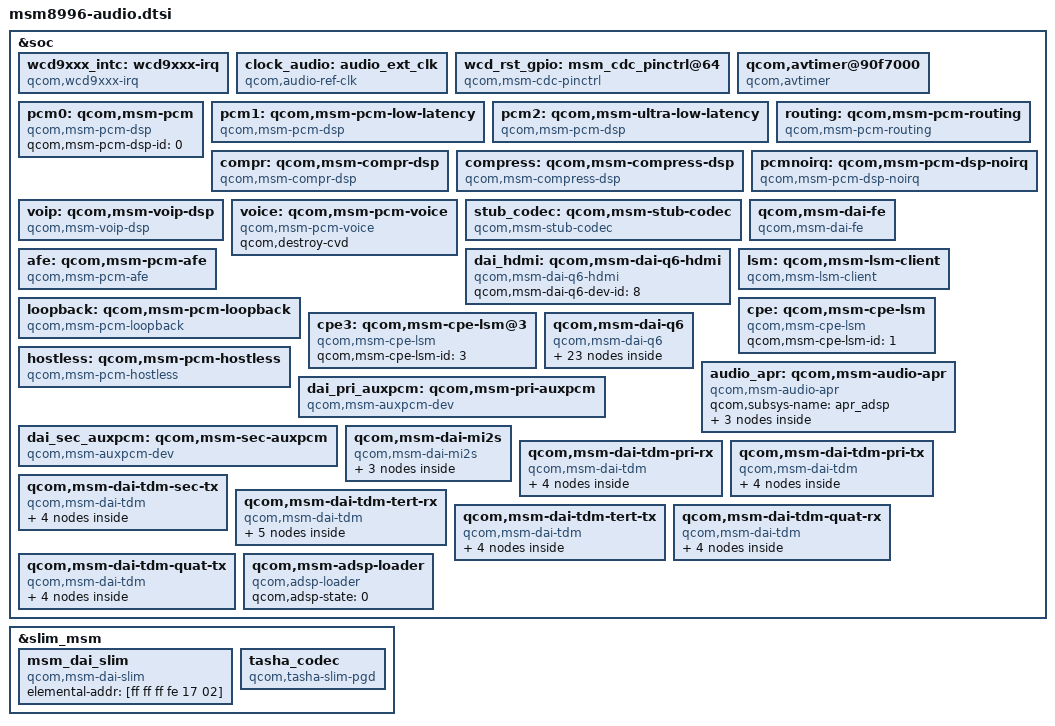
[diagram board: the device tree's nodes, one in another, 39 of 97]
/* Copyright (c) 2014-2017, The Linux Foundation. All rights reserved.
 *
 * Copyright (c) 2019 AngeloGioacchino Del Regno <kholk11@gmail.com>
 *
 * This program is free software; you can redistribute it and/or modify
 * it under the terms of the GNU General Public License version 2 and
 * only version 2 as published by the Free Software Foundation.
 *
 * This program is distributed in the hope that it will be useful,
 * but WITHOUT ANY WARRANTY; without even the implied warranty of
 * MERCHANTABILITY or FITNESS FOR A PARTICULAR PURPOSE.  See the
 * GNU General Public License for more details.
 */

#include <dt-bindings/clock/qcom,gcc-msm8996.h>
#include <dt-bindings/clock/qcom,mmcc-msm8996.h>
#include <dt-bindings/clock/qcom,audio-ext-clk.h>
#include <dt-bindings/spmi/spmi.h>
#include <dt-bindings/interrupt-controller/arm-gic.h>

&soc {
	wcd9xxx_intc: wcd9xxx-irq {
		compatible = "qcom,wcd9xxx-irq";
		interrupt-controller;
		#interrupt-cells = <1>;
		interrupt-parent = <&tlmm>;
		qcom,gpio-connect = <&tlmm 54 0>;
		pinctrl-names = "default";
		pinctrl-0 = <&wcd_intr_default>;
	};

	clock_audio: audio_ext_clk {
		compatible = "qcom,audio-ref-clk";
		qcom,audio-ref-clk-gpio = <&pm8994_gpios 15 0>; /* NOT IMPLEMENTED YET */

		qcom,codec-ext-clk-src = <3>;		    /* AUDIO_EXT_CLK_LPASS2 */
		qcom,codec-lpass-ext-clk-freq = <11289600>; /* IBIT_CLK_11_P2896_MHZ */
		qcom,codec-lpass-clk-id = <266>;	    /* SPEAKER_I2S_OSR */

		clock-names = "osr_clk";
		clocks = <&clock_rpmcc RPM_SMD_DIV_CLK1>;
		pmic-clock-names = "div_clk1";

		#clock-cells = <1>;
		qcom,use-pinctrl = <1>;
		pinctrl-names = "sleep", "active";
		pinctrl-0 = <&spkr_i2s_clk_sleep>;
		pinctrl-1 = <&spkr_i2s_clk_active>;
	};

	wcd_rst_gpio: msm_cdc_pinctrl@64 {
		compatible = "qcom,msm-cdc-pinctrl";
		qcom,cdc-rst-n-gpio = <&tlmm 64 0>;
		pinctrl-names = "aud_active", "aud_sleep";
		pinctrl-0 = <&cdc_reset_active>;
		pinctrl-1 = <&cdc_reset_sleep>;
	};

	qcom,avtimer@90f7000 {
		compatible = "qcom,avtimer";
		reg = <0x90f700c 0x4>,
		      <0x90f7010 0x4>;
		reg-names = "avtimer_lsb_addr", "avtimer_msb_addr";
		qcom,clk-div = <27>;
	};

	pcm0: qcom,msm-pcm {
		compatible = "qcom,msm-pcm-dsp";
		qcom,msm-pcm-dsp-id = <0>;
	};

	pcm1: qcom,msm-pcm-low-latency {
		compatible = "qcom,msm-pcm-dsp";
		qcom,msm-pcm-dsp-id = <1>;
		qcom,msm-pcm-low-latency;
		qcom,latency-level = "regular";
	};

	pcm2: qcom,msm-ultra-low-latency {
		compatible = "qcom,msm-pcm-dsp";
		qcom,msm-pcm-dsp-id = <2>;
		qcom,msm-pcm-low-latency;
		qcom,latency-level = "ultra";
	};

	routing: qcom,msm-pcm-routing {
		compatible = "qcom,msm-pcm-routing";
	};

	compr: qcom,msm-compr-dsp {
		compatible = "qcom,msm-compr-dsp";
	};

	compress: qcom,msm-compress-dsp {
		compatible = "qcom,msm-compress-dsp";
	};

	pcmnoirq: qcom,msm-pcm-dsp-noirq {
		compatible = "qcom,msm-pcm-dsp-noirq";
		qcom,msm-pcm-low-latency;
		qcom,latency-level = "ultra";
	};

	voip: qcom,msm-voip-dsp {
		compatible = "qcom,msm-voip-dsp";
	};

	voice: qcom,msm-pcm-voice {
		compatible = "qcom,msm-pcm-voice";
		qcom,destroy-cvd;
	};

	stub_codec: qcom,msm-stub-codec {
		compatible = "qcom,msm-stub-codec";
	};

	qcom,msm-dai-fe {
		compatible = "qcom,msm-dai-fe";
	};

	afe: qcom,msm-pcm-afe {
		compatible = "qcom,msm-pcm-afe";
	};

	dai_hdmi: qcom,msm-dai-q6-hdmi {
		compatible = "qcom,msm-dai-q6-hdmi";
		qcom,msm-dai-q6-dev-id = <8>;
	};

	lsm: qcom,msm-lsm-client {
		compatible = "qcom,msm-lsm-client";
	};

	loopback: qcom,msm-pcm-loopback {
		compatible = "qcom,msm-pcm-loopback";
	};

	cpe: qcom,msm-cpe-lsm {
		compatible = "qcom,msm-cpe-lsm";
		qcom,msm-cpe-lsm-id = <1>;
	};

	cpe3: qcom,msm-cpe-lsm@3 {
		compatible = "qcom,msm-cpe-lsm";
		qcom,msm-cpe-lsm-id = <3>;
	};

	qcom,msm-dai-q6 {
		compatible = "qcom,msm-dai-q6";
		sb_0_rx: qcom,msm-dai-q6-sb-0-rx {
			compatible = "qcom,msm-dai-q6-dev";
			qcom,msm-dai-q6-dev-id = <16384>;
		};

		sb_0_tx: qcom,msm-dai-q6-sb-0-tx {
			compatible = "qcom,msm-dai-q6-dev";
			qcom,msm-dai-q6-dev-id = <16385>;
		};

		sb_1_rx: qcom,msm-dai-q6-sb-1-rx {
			compatible = "qcom,msm-dai-q6-dev";
			qcom,msm-dai-q6-dev-id = <16386>;
		};

		sb_1_tx: qcom,msm-dai-q6-sb-1-tx {
			compatible = "qcom,msm-dai-q6-dev";
			qcom,msm-dai-q6-dev-id = <16387>;
		};

		sb_2_rx: qcom,msm-dai-q6-sb-2-rx {
			compatible = "qcom,msm-dai-q6-dev";
			qcom,msm-dai-q6-dev-id = <16388>;
		};

		sb_2_tx: qcom,msm-dai-q6-sb-2-tx {
			compatible = "qcom,msm-dai-q6-dev";
			qcom,msm-dai-q6-dev-id = <16389>;
		};

		sb_3_rx: qcom,msm-dai-q6-sb-3-rx {
			compatible = "qcom,msm-dai-q6-dev";
			qcom,msm-dai-q6-dev-id = <16390>;
		};

		sb_3_tx: qcom,msm-dai-q6-sb-3-tx {
			compatible = "qcom,msm-dai-q6-dev";
			qcom,msm-dai-q6-dev-id = <16391>;
		};

		sb_4_rx: qcom,msm-dai-q6-sb-4-rx {
			compatible = "qcom,msm-dai-q6-dev";
			qcom,msm-dai-q6-dev-id = <16392>;
		};

		sb_4_tx: qcom,msm-dai-q6-sb-4-tx {
			compatible = "qcom,msm-dai-q6-dev";
			qcom,msm-dai-q6-dev-id = <16393>;
		};

		sb_5_tx: qcom,msm-dai-q6-sb-5-tx {
			compatible = "qcom,msm-dai-q6-dev";
			qcom,msm-dai-q6-dev-id = <16395>;
		};

		bt_sco_rx: qcom,msm-dai-q6-bt-sco-rx {
			compatible = "qcom,msm-dai-q6-dev";
			qcom,msm-dai-q6-dev-id = <12288>;
		};

		bt_sco_tx: qcom,msm-dai-q6-bt-sco-tx {
			compatible = "qcom,msm-dai-q6-dev";
			qcom,msm-dai-q6-dev-id = <12289>;
		};

		afe_pcm_rx: qcom,msm-dai-q6-be-afe-pcm-rx {
			compatible = "qcom,msm-dai-q6-dev";
			qcom,msm-dai-q6-dev-id = <224>;
		};

		afe_pcm_tx: qcom,msm-dai-q6-be-afe-pcm-tx {
			compatible = "qcom,msm-dai-q6-dev";
			qcom,msm-dai-q6-dev-id = <225>;
		};

		afe_proxy_rx: com,msm-dai-q6-afe-proxy-rx {
			compatible = "qcom,msm-dai-q6-dev";
			qcom,msm-dai-q6-dev-id = <241>;
		};

		afe_proxy_tx: qcom,msm-dai-q6-afe-proxy-tx {
			compatible = "qcom,msm-dai-q6-dev";
			qcom,msm-dai-q6-dev-id = <240>;
		};

		incall_record_rx: qcom,msm-dai-q6-incall-record-rx {
			compatible = "qcom,msm-dai-q6-dev";
			qcom,msm-dai-q6-dev-id = <32771>;
		};

		incall_record_tx: qcom,msm-dai-q6-incall-record-tx {
			compatible = "qcom,msm-dai-q6-dev";
			qcom,msm-dai-q6-dev-id = <32772>;
		};

		incall_music_rx: qcom,msm-dai-q6-incall-music-rx {
			compatible = "qcom,msm-dai-q6-dev";
			qcom,msm-dai-q6-dev-id = <32773>;
		};

		incall_music2_rx: qcom,msm-dai-q6-incall-music-2-rx {
			compatible = "qcom,msm-dai-q6-dev";
			qcom,msm-dai-q6-dev-id = <32770>;
		};

		sb_5_rx: qcom,msm-dai-q6-sb-5-rx {
			compatible = "qcom,msm-dai-q6-dev";
			qcom,msm-dai-q6-dev-id = <16394>;
		};

		sb_6_rx: qcom,msm-dai-q6-sb-6-rx {
			compatible = "qcom,msm-dai-q6-dev";
			qcom,msm-dai-q6-dev-id = <16396>;
		};

	};

	hostless: qcom,msm-pcm-hostless {
		compatible = "qcom,msm-pcm-hostless";
	};

	audio_apr: qcom,msm-audio-apr {
		compatible = "qcom,msm-audio-apr";
		qcom,subsys-name = "apr_adsp";

		q6core: q6core {
			compatible = "qcom,q6core-audio";
		};

		msm_audio_ion: qcom,msm-audio-ion {
			compatible = "qcom,msm-audio-ion";
			qcom,smmu-version = <2>;
			qcom,smmu-enabled;
			iommus = <&lpass_q6_smmu 1>;
		};
	};

	dai_pri_auxpcm: qcom,msm-pri-auxpcm {
		compatible = "qcom,msm-auxpcm-dev";
		qcom,msm-cpudai-auxpcm-mode = <0>, <0>;
		qcom,msm-cpudai-auxpcm-sync = <1>, <1>;
		qcom,msm-cpudai-auxpcm-frame = <5>, <4>;
		qcom,msm-cpudai-auxpcm-quant = <2>, <2>;
		qcom,msm-cpudai-auxpcm-num-slots = <1>, <1>;
		qcom,msm-cpudai-auxpcm-slot-mapping = <1>, <1>;
		qcom,msm-cpudai-auxpcm-data = <0>, <0>;
		qcom,msm-cpudai-auxpcm-pcm-clk-rate = <2048000>, <2048000>;
		qcom,msm-auxpcm-interface = "primary";
		qcom,msm-cpudai-afe-clk-ver = <2>;
		pinctrl-names = "default", "sleep";
		pinctrl-0 = <&pri_aux_pcm_active &pri_aux_pcm_din_active
			     &pri_aux_pcm_dout_active>;
		pinctrl-1 = <&pri_aux_pcm_sleep &pri_aux_pcm_din_sleep
			     &pri_aux_pcm_dout_sleep>;
	};

	dai_sec_auxpcm: qcom,msm-sec-auxpcm {
		compatible = "qcom,msm-auxpcm-dev";
		qcom,msm-cpudai-auxpcm-mode = <0>, <0>;
		qcom,msm-cpudai-auxpcm-sync = <1>, <1>;
		qcom,msm-cpudai-auxpcm-frame = <5>, <4>;
		qcom,msm-cpudai-auxpcm-quant = <2>, <2>;
		qcom,msm-cpudai-auxpcm-num-slots = <1>, <1>;
		qcom,msm-cpudai-auxpcm-slot-mapping = <1>, <1>;
		qcom,msm-cpudai-auxpcm-data = <0>, <0>;
		qcom,msm-cpudai-auxpcm-pcm-clk-rate = <2048000>, <2048000>;
		qcom,msm-auxpcm-interface = "secondary";
		qcom,msm-cpudai-afe-clk-ver = <2>;
	};

	qcom,msm-dai-mi2s {
		compatible = "qcom,msm-dai-mi2s";
		dai_mi2s_sec: qcom,msm-dai-q6-mi2s-sec {
			compatible = "qcom,msm-dai-q6-mi2s";
			qcom,msm-dai-q6-mi2s-dev-id = <1>;
			qcom,msm-mi2s-rx-lines = <1>;
			qcom,msm-mi2s-tx-lines = <0>;
		};

		dai_mi2s: qcom,msm-dai-q6-mi2s-tert {
			compatible = "qcom,msm-dai-q6-mi2s";
			qcom,msm-dai-q6-mi2s-dev-id = <2>;
			qcom,msm-mi2s-rx-lines = <2>;
			qcom,msm-mi2s-tx-lines = <1>;
			pinctrl-names = "default", "sleep";
			pinctrl-0 = <&tert_mi2s_active &tert_mi2s_sd0_active>;
			pinctrl-1 = <&tert_mi2s_sleep &tert_mi2s_sd0_sleep>;
		};

		dai_mi2s_quat: qcom,msm-dai-q6-mi2s-quat {
			compatible = "qcom,msm-dai-q6-mi2s";
			qcom,msm-dai-q6-mi2s-dev-id = <3>;
			qcom,msm-mi2s-rx-lines = <1>;
			qcom,msm-mi2s-tx-lines = <0>;
		};
	};

	qcom,msm-dai-tdm-pri-rx {
		compatible = "qcom,msm-dai-tdm";
		qcom,msm-cpudai-tdm-group-id = <37120>;
		qcom,msm-cpudai-tdm-group-num-ports = <4>;
		qcom,msm-cpudai-tdm-group-port-id = <36864 36866 36868 36870>;
		qcom,msm-cpudai-tdm-clk-rate = <12288000>;
		qcom,msm-cpudai-tdm-clk-internal = <1>;
		qcom,msm-cpudai-tdm-sync-mode = <0>;
		qcom,msm-cpudai-tdm-sync-src = <1>;
		qcom,msm-cpudai-tdm-data-out = <0>;
		qcom,msm-cpudai-tdm-invert-sync = <0>;
		qcom,msm-cpudai-tdm-data-delay = <1>;
		qcom,msm-cpudai-tdm-clk-attribute = /bits/ 16 <1>;
		dai_pri_tdm_rx_0: qcom,msm-dai-q6-tdm-pri-rx-0 {
			compatible = "qcom,msm-dai-q6-tdm";
			qcom,msm-cpudai-tdm-dev-id = <36864>;
			qcom,msm-cpudai-tdm-data-align = <0>;
		};

		dai_pri_tdm_rx_1: qcom,msm-dai-q6-tdm-pri-rx-1 {
			compatible = "qcom,msm-dai-q6-tdm";
			qcom,msm-cpudai-tdm-dev-id = <36866>;
			qcom,msm-cpudai-tdm-data-align = <0>;
		};

		dai_pri_tdm_rx_2: qcom,msm-dai-q6-tdm-pri-rx-2 {
			compatible = "qcom,msm-dai-q6-tdm";
			qcom,msm-cpudai-tdm-dev-id = <36868>;
			qcom,msm-cpudai-tdm-data-align = <0>;
		};

		dai_pri_tdm_rx_3: qcom,msm-dai-q6-tdm-pri-rx-3 {
			compatible = "qcom,msm-dai-q6-tdm";
			qcom,msm-cpudai-tdm-dev-id = <36870>;
			qcom,msm-cpudai-tdm-data-align = <0>;
		};
	};

	qcom,msm-dai-tdm-pri-tx {
		compatible = "qcom,msm-dai-tdm";
		qcom,msm-cpudai-tdm-group-id = <37121>;
		qcom,msm-cpudai-tdm-group-num-ports = <4>;
		qcom,msm-cpudai-tdm-group-port-id = <36865 36867 36869 36871>;
		qcom,msm-cpudai-tdm-clk-rate = <12288000>;
		qcom,msm-cpudai-tdm-clk-internal = <1>;
		qcom,msm-cpudai-tdm-sync-mode = <0>;
		qcom,msm-cpudai-tdm-sync-src = <1>;
		qcom,msm-cpudai-tdm-data-out = <0>;
		qcom,msm-cpudai-tdm-invert-sync = <0>;
		qcom,msm-cpudai-tdm-data-delay = <1>;
		qcom,msm-cpudai-tdm-clk-attribute = /bits/ 16 <1>;
		dai_pri_tdm_tx_0: qcom,msm-dai-q6-tdm-pri-tx-0 {
			compatible = "qcom,msm-dai-q6-tdm";
			qcom,msm-cpudai-tdm-dev-id = <36865>;
			qcom,msm-cpudai-tdm-data-align = <0>;
		};

		dai_pri_tdm_tx_1: qcom,msm-dai-q6-tdm-pri-tx-1 {
			compatible = "qcom,msm-dai-q6-tdm";
			qcom,msm-cpudai-tdm-dev-id = <36867>;
			qcom,msm-cpudai-tdm-data-align = <0>;
		};

		dai_pri_tdm_tx_2: qcom,msm-dai-q6-tdm-pri-tx-2 {
			compatible = "qcom,msm-dai-q6-tdm";
			qcom,msm-cpudai-tdm-dev-id = <36869>;
			qcom,msm-cpudai-tdm-data-align = <0>;
		};

		dai_pri_tdm_tx_3: qcom,msm-dai-q6-tdm-pri-tx-3 {
			compatible = "qcom,msm-dai-q6-tdm";
			qcom,msm-cpudai-tdm-dev-id = <36871>;
			qcom,msm-cpudai-tdm-data-align = <0>;
		};
	};

	qcom,msm-dai-tdm-sec-tx {
		compatible = "qcom,msm-dai-tdm";
		qcom,msm-cpudai-tdm-group-id = <37137>;
		qcom,msm-cpudai-tdm-group-num-ports = <4>;
		qcom,msm-cpudai-tdm-group-port-id = <36881 36883 36885 36887>;
		qcom,msm-cpudai-tdm-clk-rate = <12288000>;
		qcom,msm-cpudai-tdm-clk-internal = <0>;
		qcom,msm-cpudai-tdm-sync-mode = <1>;
		qcom,msm-cpudai-tdm-sync-src = <0>;
		qcom,msm-cpudai-tdm-data-out = <0>;
		qcom,msm-cpudai-tdm-invert-sync = <0>;
		qcom,msm-cpudai-tdm-data-delay = <0>;
		dai_sec_tdm_tx_0: qcom,msm-dai-q6-tdm-sec-tx-0 {
			compatible = "qcom,msm-dai-q6-tdm";
			qcom,msm-cpudai-tdm-dev-id = <36881>;
			qcom,msm-cpudai-tdm-data-align = <0>;
		};

		dai_sec_tdm_tx_1: qcom,msm-dai-q6-tdm-sec-tx-1 {
			compatible = "qcom,msm-dai-q6-tdm";
			qcom,msm-cpudai-tdm-dev-id = <36883>;
			qcom,msm-cpudai-tdm-data-align = <0>;
		};

		dai_sec_tdm_tx_2: qcom,msm-dai-q6-tdm-sec-tx-2 {
			compatible = "qcom,msm-dai-q6-tdm";
			qcom,msm-cpudai-tdm-dev-id = <36885>;
			qcom,msm-cpudai-tdm-data-align = <0>;
		};

		dai_sec_tdm_tx_3: qcom,msm-dai-q6-tdm-sec-tx-3 {
			compatible = "qcom,msm-dai-q6-tdm";
			qcom,msm-cpudai-tdm-dev-id = <36887>;
			qcom,msm-cpudai-tdm-data-align = <0>;
		};
	};

	qcom,msm-dai-tdm-tert-rx {
		compatible = "qcom,msm-dai-tdm";
		qcom,msm-cpudai-tdm-group-id = <37152>;
		qcom,msm-cpudai-tdm-group-num-ports = <5>;
		qcom,msm-cpudai-tdm-group-port-id = <36896 36898 36900
							36902 36904>;
		qcom,msm-cpudai-tdm-clk-rate = <12288000>;
		qcom,msm-cpudai-tdm-clk-internal = <0>;
		qcom,msm-cpudai-tdm-sync-mode = <1>;
		qcom,msm-cpudai-tdm-sync-src = <0>;
		qcom,msm-cpudai-tdm-data-out = <0>;
		qcom,msm-cpudai-tdm-invert-sync = <0>;
		qcom,msm-cpudai-tdm-data-delay = <0>;
		dai_tert_tdm_rx_0: qcom,msm-dai-q6-tdm-tert-rx-0 {
			compatible = "qcom,msm-dai-q6-tdm";
			qcom,msm-cpudai-tdm-dev-id = <36896>;
			qcom,msm-cpudai-tdm-data-align = <0>;
		};

		dai_tert_tdm_rx_1: qcom,msm-dai-q6-tdm-tert-rx-1 {
			compatible = "qcom,msm-dai-q6-tdm";
			qcom,msm-cpudai-tdm-dev-id = <36898>;
			qcom,msm-cpudai-tdm-data-align = <0>;
		};

		dai_tert_tdm_rx_2: qcom,msm-dai-q6-tdm-tert-rx-2 {
			compatible = "qcom,msm-dai-q6-tdm";
			qcom,msm-cpudai-tdm-dev-id = <36900>;
			qcom,msm-cpudai-tdm-data-align = <0>;
		};

		dai_tert_tdm_rx_3: qcom,msm-dai-q6-tdm-tert-rx-3 {
			compatible = "qcom,msm-dai-q6-tdm";
			qcom,msm-cpudai-tdm-dev-id = <36902>;
			qcom,msm-cpudai-tdm-data-align = <0>;
		};

		dai_tert_tdm_rx_4: qcom,msm-dai-q6-tdm-tert-rx-4 {
			compatible = "qcom,msm-dai-q6-tdm";
			qcom,msm-cpudai-tdm-dev-id = <36904>;
			qcom,msm-cpudai-tdm-data-align = <0>;
		};
	};

	qcom,msm-dai-tdm-tert-tx {
		compatible = "qcom,msm-dai-tdm";
		qcom,msm-cpudai-tdm-group-id = <37153>;
		qcom,msm-cpudai-tdm-group-num-ports = <4>;
		qcom,msm-cpudai-tdm-group-port-id = <36897 36899 36901 36903>;
		qcom,msm-cpudai-tdm-clk-rate = <12288000>;
		qcom,msm-cpudai-tdm-clk-internal = <0>;
		qcom,msm-cpudai-tdm-sync-mode = <1>;
		qcom,msm-cpudai-tdm-sync-src = <0>;
		qcom,msm-cpudai-tdm-data-out = <0>;
		qcom,msm-cpudai-tdm-invert-sync = <0>;
		qcom,msm-cpudai-tdm-data-delay = <0>;
		dai_tert_tdm_tx_0: qcom,msm-dai-q6-tdm-tert-tx-0 {
			compatible = "qcom,msm-dai-q6-tdm";
			qcom,msm-cpudai-tdm-dev-id = <36897>;
			qcom,msm-cpudai-tdm-data-align = <0>;
		};

		dai_tert_tdm_tx_1: qcom,msm-dai-q6-tdm-tert-tx-1 {
			compatible = "qcom,msm-dai-q6-tdm";
			qcom,msm-cpudai-tdm-dev-id = <36899>;
			qcom,msm-cpudai-tdm-data-align = <0>;
		};

		dai_tert_tdm_tx_2: qcom,msm-dai-q6-tdm-tert-tx-2 {
			compatible = "qcom,msm-dai-q6-tdm";
			qcom,msm-cpudai-tdm-dev-id = <36901>;
			qcom,msm-cpudai-tdm-data-align = <0>;
		};

		dai_tert_tdm_tx_3: qcom,msm-dai-q6-tdm-tert-tx-3 {
			compatible = "qcom,msm-dai-q6-tdm";
			qcom,msm-cpudai-tdm-dev-id = <36903>;
			qcom,msm-cpudai-tdm-data-align = <0>;
		};
	};

	qcom,msm-dai-tdm-quat-rx {
		compatible = "qcom,msm-dai-tdm";
		qcom,msm-cpudai-tdm-group-id = <37168>;
		qcom,msm-cpudai-tdm-group-num-ports = <4>;
		qcom,msm-cpudai-tdm-group-port-id = <36912 36914 36916 36918>;
		qcom,msm-cpudai-tdm-clk-rate = <12288000>;
		qcom,msm-cpudai-tdm-clk-internal = <0>;
		qcom,msm-cpudai-tdm-sync-mode = <1>;
		qcom,msm-cpudai-tdm-sync-src = <0>;
		qcom,msm-cpudai-tdm-data-out = <0>;
		qcom,msm-cpudai-tdm-invert-sync = <0>;
		qcom,msm-cpudai-tdm-data-delay = <0>;
		dai_quat_tdm_rx_0: qcom,msm-dai-q6-tdm-quat-rx-0 {
			compatible = "qcom,msm-dai-q6-tdm";
			qcom,msm-cpudai-tdm-dev-id = <36912>;
			qcom,msm-cpudai-tdm-data-align = <0>;
		};

		dai_quat_tdm_rx_1: qcom,msm-dai-q6-tdm-quat-rx-1 {
			compatible = "qcom,msm-dai-q6-tdm";
			qcom,msm-cpudai-tdm-dev-id = <36914>;
			qcom,msm-cpudai-tdm-data-align = <0>;
		};

		dai_quat_tdm_rx_2: qcom,msm-dai-q6-tdm-quat-rx-2 {
			compatible = "qcom,msm-dai-q6-tdm";
			qcom,msm-cpudai-tdm-dev-id = <36916>;
			qcom,msm-cpudai-tdm-data-align = <0>;
		};

		dai_quat_tdm_rx_3: qcom,msm-dai-q6-tdm-quat-rx-3 {
			compatible = "qcom,msm-dai-q6-tdm";
			qcom,msm-cpudai-tdm-dev-id = <36918>;
			qcom,msm-cpudai-tdm-data-align = <0>;
		};
	};

	qcom,msm-dai-tdm-quat-tx {
		compatible = "qcom,msm-dai-tdm";
		qcom,msm-cpudai-tdm-group-id = <37169>;
		qcom,msm-cpudai-tdm-group-num-ports = <4>;
		qcom,msm-cpudai-tdm-group-port-id = <36913 36915 36917 36919>;
		qcom,msm-cpudai-tdm-clk-rate = <12288000>;
		qcom,msm-cpudai-tdm-clk-internal = <0>;
		qcom,msm-cpudai-tdm-sync-mode = <1>;
		qcom,msm-cpudai-tdm-sync-src = <0>;
		qcom,msm-cpudai-tdm-data-out = <0>;
		qcom,msm-cpudai-tdm-invert-sync = <0>;
		qcom,msm-cpudai-tdm-data-delay = <0>;
		dai_quat_tdm_tx_0: qcom,msm-dai-q6-tdm-quat-tx-0 {
			compatible = "qcom,msm-dai-q6-tdm";
			qcom,msm-cpudai-tdm-dev-id = <36913>;
			qcom,msm-cpudai-tdm-data-align = <0>;
		};

		dai_quat_tdm_tx_1: qcom,msm-dai-q6-tdm-quat-tx-1 {
			compatible = "qcom,msm-dai-q6-tdm";
			qcom,msm-cpudai-tdm-dev-id = <36915>;
			qcom,msm-cpudai-tdm-data-align = <0>;
		};

		dai_quat_tdm_tx_2: qcom,msm-dai-q6-tdm-quat-tx-2 {
			compatible = "qcom,msm-dai-q6-tdm";
			qcom,msm-cpudai-tdm-dev-id = <36917>;
			qcom,msm-cpudai-tdm-data-align = <0>;
		};

		dai_quat_tdm_tx_3: qcom,msm-dai-q6-tdm-quat-tx-3 {
			compatible = "qcom,msm-dai-q6-tdm";
			qcom,msm-cpudai-tdm-dev-id = <36919>;
			qcom,msm-cpudai-tdm-data-align = <0>;
		};
	};

	qcom,msm-adsp-loader {
		status = "ok";
		compatible = "qcom,adsp-loader";
		qcom,adsp-state = <0>;
	};
};

&q6core {
	snd_card_9335: sound-9335 {
		compatible = "qcom,msm8996-asoc-snd-tasha";
		qcom,model = "msm8996-tasha-snd-card";

		qcom,audio-routing =
			"AIF4 VI", "MCLK",
			"RX_BIAS", "MCLK",
			"MADINPUT", "MCLK",
			"AMIC2", "MIC BIAS2",
			"MIC BIAS2", "Headset Mic",
			"AMIC3", "MIC BIAS2",
			"MIC BIAS2", "ANCRight Headset Mic",
			"AMIC4", "MIC BIAS2",
			"MIC BIAS2", "ANCLeft Headset Mic",
			"AMIC5", "MIC BIAS3",
			"MIC BIAS3", "Handset Mic",
			"AMIC6", "MIC BIAS4",
			"MIC BIAS4", "Analog Mic6",
			"DMIC0", "MIC BIAS1",
			"MIC BIAS1", "Digital Mic0",
			"DMIC1", "MIC BIAS1",
			"MIC BIAS1", "Digital Mic1",
			"DMIC2", "MIC BIAS3",
			"MIC BIAS3", "Digital Mic2",
			"DMIC3", "MIC BIAS3",
			"MIC BIAS3", "Digital Mic3",
			"DMIC4", "MIC BIAS4",
			"MIC BIAS4", "Digital Mic4",
			"DMIC5", "MIC BIAS4",
			"MIC BIAS4", "Digital Mic5",
			"SpkrLeft IN", "SPK1 OUT",
			"SpkrRight IN", "SPK2 OUT";

		qcom,msm-mbhc-hphl-swh = <0>;
		qcom,msm-mbhc-gnd-swh = <0>;
		qcom,tasha-mclk-clk-freq = <9600000>;
		asoc-platform = <&pcm0>, <&pcm1>, <&pcm2>, <&voip>, <&voice>,
				<&loopback>, <&compress>, <&hostless>,
				<&afe>, <&lsm>, <&routing>, <&cpe>,
				<&compr>, <&pcmnoirq>, <&cpe3>;
		asoc-platform-names = "msm-pcm-dsp.0", "msm-pcm-dsp.1", "msm-pcm-dsp.2",
				"msm-voip-dsp", "msm-pcm-voice", "msm-pcm-loopback",
				"msm-compress-dsp", "msm-pcm-hostless", "msm-pcm-afe",
				"msm-lsm-client", "msm-pcm-routing", "msm-cpe-lsm",
				"msm-compr-dsp", "msm-pcm-dsp-noirq",
				"msm-cpe-lsm.3";
		asoc-cpu = <&dai_pri_auxpcm>, <&dai_sec_auxpcm>, <&dai_hdmi>, <&dai_mi2s>,
				<&sb_0_rx>, <&sb_0_tx>, <&sb_1_rx>, <&sb_1_tx>,
				<&sb_2_rx>, <&sb_2_tx>, <&sb_3_rx>, <&sb_3_tx>,
				<&sb_4_rx>, <&sb_4_tx>, <&sb_5_tx>, <&afe_pcm_rx>,
				<&afe_pcm_tx>, <&afe_proxy_rx>, <&afe_proxy_tx>,
				<&incall_record_rx>, <&incall_record_tx>,
				<&incall_music_rx>, <&incall_music2_rx>,
				<&sb_5_rx>, <&sb_6_rx>;
		asoc-cpu-names = "msm-dai-q6-auxpcm.1", "msm-dai-q6-auxpcm.2",
				"msm-dai-q6-hdmi.8", "msm-dai-q6-mi2s.2",
				"msm-dai-q6-dev.16384", "msm-dai-q6-dev.16385",
				"msm-dai-q6-dev.16386", "msm-dai-q6-dev.16387",
				"msm-dai-q6-dev.16388", "msm-dai-q6-dev.16389",
				"msm-dai-q6-dev.16390", "msm-dai-q6-dev.16391",
				"msm-dai-q6-dev.16392", "msm-dai-q6-dev.16393",
				"msm-dai-q6-dev.16395", "msm-dai-q6-dev.224",
				"msm-dai-q6-dev.225", "msm-dai-q6-dev.241",
				"msm-dai-q6-dev.240", "msm-dai-q6-dev.32771",
				"msm-dai-q6-dev.32772", "msm-dai-q6-dev.32773",
				"msm-dai-q6-dev.32770", "msm-dai-q6-dev.16394",
				"msm-dai-q6-dev.16396";
		asoc-codec = <&stub_codec>;
		asoc-codec-names = "msm-stub-codec.1";
	};
};

&slim_msm {
	msm_dai_slim {
		compatible = "qcom,msm-dai-slim";
		elemental-addr = [ff ff ff fe 17 02];
	};

	tasha_codec {
		compatible = "qcom,tasha-slim-pgd";
		elemental-addr = [00 01 A0 01 17 02];

		interrupt-parent = <&wcd9xxx_intc>;
		interrupts = <0 1 2 3 4 5 6 7 8 9 10 11 12 13 14 15 16
			      17 18 19 20 21 22 23 24 25 26 27 28 29
			      30>;

		qcom,wcd-rst-gpio-node = <&wcd_rst_gpio>;

		clock-names = "wcd_clk", "wcd_native_clk";
		clocks = <&clock_audio 0>, /* AUDIO_EXT_CLK_PMI */
			 <&clock_audio 3>; /* AUDIO_EXT_CLK_LPASS2 */

		cdc-vdd-buck-supply = <&pm8994_s4>;
		qcom,cdc-vdd-buck-voltage = <1800000 1800000>;
		qcom,cdc-vdd-buck-current = <650000>;

		cdc-buck-sido-supply = <&pm8994_s4>;
		qcom,cdc-buck-sido-voltage = <1800000 1800000>;
		qcom,cdc-buck-sido-current = <250000>;

		cdc-vdd-tx-h-supply = <&pm8994_s4>;
		qcom,cdc-vdd-tx-h-voltage = <1800000 1800000>;
		qcom,cdc-vdd-tx-h-current = <25000>;

		cdc-vdd-rx-h-supply = <&pm8994_s4>;
		qcom,cdc-vdd-rx-h-voltage = <1800000 1800000>;
		qcom,cdc-vdd-rx-h-current = <25000>;

		cdc-vddpx-1-supply = <&pm8994_s4>;
		qcom,cdc-vddpx-1-voltage = <1800000 1800000>;
		qcom,cdc-vddpx-1-current = <10000>;

		qcom,cdc-static-supplies = "cdc-vdd-buck",
					   "cdc-buck-sido",
					   "cdc-vdd-tx-h",
					   "cdc-vdd-rx-h",
					   "cdc-vddpx-1";

		qcom,cdc-micbias1-mv = <1800>;
		qcom,cdc-micbias2-mv = <1800>;
		qcom,cdc-micbias3-mv = <1800>;
		qcom,cdc-micbias4-mv = <1800>;

		qcom,cdc-mclk-clk-rate = <9600000>;
		qcom,cdc-slim-ifd = "tasha-slim-ifd";
		qcom,cdc-slim-ifd-elemental-addr = [00 00 A0 01 17 02];
		qcom,cdc-dmic-sample-rate = <4800000>;
		qcom,cdc-mad-dmic-rate = <600000>;
		qcom,cdc-ecpp-dmic-rate = <1200000>;
		qcom,cdc-dmic-clk-drv-strength = <2>;
	};
};
